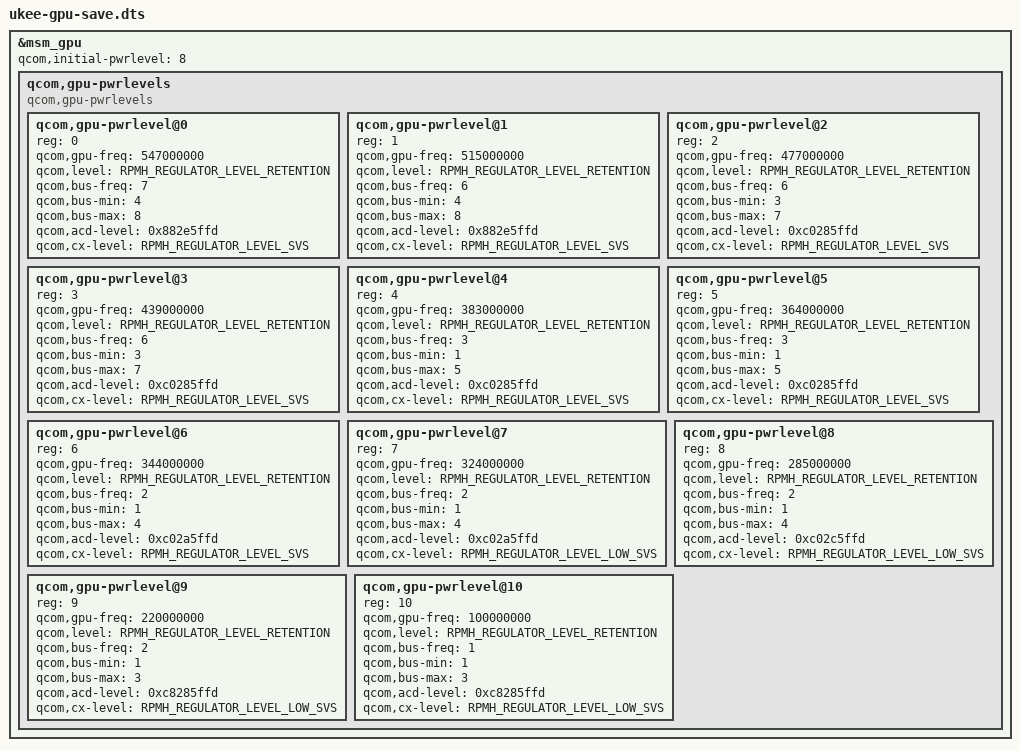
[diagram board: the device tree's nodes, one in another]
/*
 * DoraCore: ukee.dtb with an Adreno 725 undervolt + underclock (battery saving)
 * power level table, from the KonaBess profile "battery save: underclock + undervolt, under bus frequency, added intermediate freqs | SD 7+ GEN 2".
 * Generated by tools/gen-gpu-profiles.py; only the GPU (GX) rail
 * levels change, CX votes stay as stock. Running the GPU outside the
 * stock table may crash, freeze or damage the device.
 */

#include "ukee.dts"

&msm_gpu {
	/delete-node/ qcom,gpu-pwrlevels;
};

&msm_gpu {
	qcom,initial-pwrlevel = <8>;

	qcom,gpu-pwrlevels {
		#address-cells = <1>;
		#size-cells = <0>;

		compatible = "qcom,gpu-pwrlevels";

		/* 547 MHz (not in stock, profile level 2) */
		qcom,gpu-pwrlevel@0 {
			reg = <0>;
			qcom,gpu-freq = <547000000>;
			qcom,level = <RPMH_REGULATOR_LEVEL_RETENTION>;

			qcom,bus-freq = <7>;
			qcom,bus-min = <4>;
			qcom,bus-max = <8>;

			qcom,acd-level = <0x882e5ffd>;
			qcom,cx-level = <RPMH_REGULATOR_LEVEL_SVS>;
		};

		/* 515 MHz (stock SVS, profile level 1) */
		qcom,gpu-pwrlevel@1 {
			reg = <1>;
			qcom,gpu-freq = <515000000>;
			qcom,level = <RPMH_REGULATOR_LEVEL_RETENTION>;

			qcom,bus-freq = <6>;
			qcom,bus-min = <4>;
			qcom,bus-max = <8>;

			qcom,acd-level = <0x882e5ffd>;
			qcom,cx-level = <RPMH_REGULATOR_LEVEL_SVS>;
		};

		/* 477 MHz (not in stock, profile level 1) */
		qcom,gpu-pwrlevel@2 {
			reg = <2>;
			qcom,gpu-freq = <477000000>;
			qcom,level = <RPMH_REGULATOR_LEVEL_RETENTION>;

			qcom,bus-freq = <6>;
			qcom,bus-min = <3>;
			qcom,bus-max = <7>;

			qcom,acd-level = <0xc0285ffd>;
			qcom,cx-level = <RPMH_REGULATOR_LEVEL_SVS>;
		};

		/* 439 MHz (stock LOW_SVS_L2, profile level 1) */
		qcom,gpu-pwrlevel@3 {
			reg = <3>;
			qcom,gpu-freq = <439000000>;
			qcom,level = <RPMH_REGULATOR_LEVEL_RETENTION>;

			qcom,bus-freq = <6>;
			qcom,bus-min = <3>;
			qcom,bus-max = <7>;

			qcom,acd-level = <0xc0285ffd>;
			qcom,cx-level = <RPMH_REGULATOR_LEVEL_SVS>;
		};

		/* 383 MHz (not in stock, profile level 1) */
		qcom,gpu-pwrlevel@4 {
			reg = <4>;
			qcom,gpu-freq = <383000000>;
			qcom,level = <RPMH_REGULATOR_LEVEL_RETENTION>;

			qcom,bus-freq = <3>;
			qcom,bus-min = <1>;
			qcom,bus-max = <5>;

			qcom,acd-level = <0xc0285ffd>;
			qcom,cx-level = <RPMH_REGULATOR_LEVEL_SVS>;
		};

		/* 364 MHz (stock LOW_SVS_L1, profile level 1) */
		qcom,gpu-pwrlevel@5 {
			reg = <5>;
			qcom,gpu-freq = <364000000>;
			qcom,level = <RPMH_REGULATOR_LEVEL_RETENTION>;

			qcom,bus-freq = <3>;
			qcom,bus-min = <1>;
			qcom,bus-max = <5>;

			qcom,acd-level = <0xc0285ffd>;
			qcom,cx-level = <RPMH_REGULATOR_LEVEL_SVS>;
		};

		/* 344 MHz (not in stock, profile level 1) */
		qcom,gpu-pwrlevel@6 {
			reg = <6>;
			qcom,gpu-freq = <344000000>;
			qcom,level = <RPMH_REGULATOR_LEVEL_RETENTION>;

			qcom,bus-freq = <2>;
			qcom,bus-min = <1>;
			qcom,bus-max = <4>;

			qcom,acd-level = <0xc02a5ffd>;
			qcom,cx-level = <RPMH_REGULATOR_LEVEL_SVS>;
		};

		/* 324 MHz (stock LOW_SVS, profile level 1) */
		qcom,gpu-pwrlevel@7 {
			reg = <7>;
			qcom,gpu-freq = <324000000>;
			qcom,level = <RPMH_REGULATOR_LEVEL_RETENTION>;

			qcom,bus-freq = <2>;
			qcom,bus-min = <1>;
			qcom,bus-max = <4>;

			qcom,acd-level = <0xc02a5ffd>;
			qcom,cx-level = <RPMH_REGULATOR_LEVEL_LOW_SVS>;
		};

		/* 285 MHz (stock LOW_SVS_D1, profile level 1) */
		qcom,gpu-pwrlevel@8 {
			reg = <8>;
			qcom,gpu-freq = <285000000>;
			qcom,level = <RPMH_REGULATOR_LEVEL_RETENTION>;

			qcom,bus-freq = <2>;
			qcom,bus-min = <1>;
			qcom,bus-max = <4>;

			qcom,acd-level = <0xc02c5ffd>;
			qcom,cx-level = <RPMH_REGULATOR_LEVEL_LOW_SVS>;
		};

		/* 220 MHz (stock MIN_SVS, profile level 1) */
		qcom,gpu-pwrlevel@9 {
			reg = <9>;
			qcom,gpu-freq = <220000000>;
			qcom,level = <RPMH_REGULATOR_LEVEL_RETENTION>;

			qcom,bus-freq = <2>;
			qcom,bus-min = <1>;
			qcom,bus-max = <3>;

			qcom,acd-level = <0xc8285ffd>;
			qcom,cx-level = <RPMH_REGULATOR_LEVEL_LOW_SVS>;
		};

		/* 100 MHz (not in stock, profile level 1) */
		qcom,gpu-pwrlevel@10 {
			reg = <10>;
			qcom,gpu-freq = <100000000>;
			qcom,level = <RPMH_REGULATOR_LEVEL_RETENTION>;

			qcom,bus-freq = <1>;
			qcom,bus-min = <1>;
			qcom,bus-max = <3>;

			qcom,acd-level = <0xc8285ffd>;
			qcom,cx-level = <RPMH_REGULATOR_LEVEL_LOW_SVS>;
		};
	};
};
